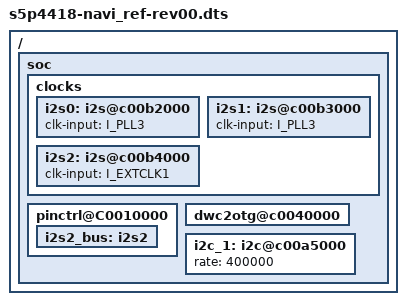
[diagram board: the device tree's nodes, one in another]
/*
 * Copyright (C) 2016  Nexell Co., Ltd.
 * Author: Youngbok, Park <ybpark@nexell.co.kr>
 *
 * This program is free software; you can redistribute it and/or
 * modify it under the terms of the GNU General Public License
 * as published by the Free Software Foundation; either version 2
 * of the License, or (at your option) any later version.
 *
 * This program is distributed in the hope that it will be useful,
 * but WITHOUT ANY WARRANTY; without even the implied warranty of
 * MERCHANTABILITY or FITNESS FOR A PARTICULAR PURPOSE.  See the
 * GNU General Public License for more details.
 *
 * You should have received a copy of the GNU General Public License
 * along with this program.  If not, see <http://www.gnu.org/licenses/>.
 */

/dts-v1/;
#include "s5p4418-navi_ref-common.dtsi"
#include "s5p4418-audio-dfs-pll3.dtsi"
/ {
	soc {
		clocks {
			i2s0:i2s@c00b2000 {
				clk-input = <I_PLL3>;
			};

			i2s1:i2s@c00b3000 {
				clk-input = <I_PLL3>;
			};

			i2s2:i2s@c00b4000 {
				clk-input = <I_EXTCLK1>;
			};
		};

		pinctrl@C0010000 {
			i2s2_bus:i2s2 {
				/delete-node/ i2s2-mclk;
			};
		};

		dwc2otg@c0040000 {
			/delete-property/ gpios;
		};

		i2c_1:i2c@c00a5000 {
			rate = <400000>;
		};
	};
};
